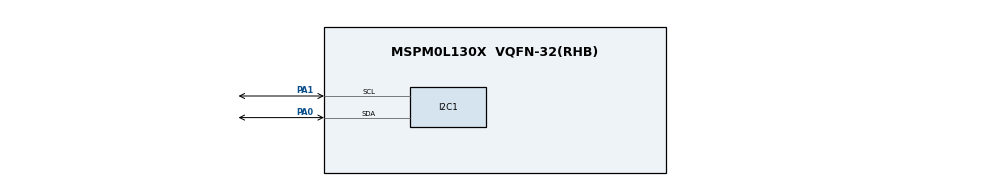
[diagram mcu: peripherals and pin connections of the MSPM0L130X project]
/**
 * @cliArgs --device "MSPM0L130X" --part "Default" --package "VQFN-32(RHB)" --product "mspm0_sdk@2.03.00.08"
 * @versions {"tool":"1.22.0+3893"}
 */

/**
 * Import the modules used in this configuration.
 */
const GPIO   = scripting.addModule("/ti/driverlib/GPIO", {}, false);
const GPIO1  = GPIO.addInstance();
const GPIO2  = GPIO.addInstance();
const GPIO3  = GPIO.addInstance();
const I2C    = scripting.addModule("/ti/driverlib/I2C", {}, false);
const I2C1   = I2C.addInstance();
const SYSCTL = scripting.addModule("/ti/driverlib/SYSCTL");
const TIMER  = scripting.addModule("/ti/driverlib/TIMER", {}, false);
const TIMER1 = TIMER.addInstance();

/**
 * Write custom configuration values to the imported modules.
 */
GPIO1.$name                         = "GPIO_LED";
GPIO1.port                          = "PORTA";
GPIO1.associatedPins[0].assignedPin = "7";
GPIO1.associatedPins[0].$name       = "STATUS";

const Board = scripting.addModule("/ti/driverlib/Board", {}, false);

GPIO2.$name                         = "GPIO_DAC";
GPIO2.port                          = "PORTA";
GPIO2.associatedPins.create(8);
GPIO2.associatedPins[0].$name       = "B7";
GPIO2.associatedPins[0].assignedPin = "11";
GPIO2.associatedPins[1].$name       = "B6";
GPIO2.associatedPins[1].assignedPin = "12";
GPIO2.associatedPins[2].$name       = "B5";
GPIO2.associatedPins[2].assignedPin = "13";
GPIO2.associatedPins[3].$name       = "B4";
GPIO2.associatedPins[3].assignedPin = "14";
GPIO2.associatedPins[4].$name       = "B3";
GPIO2.associatedPins[4].assignedPin = "15";
GPIO2.associatedPins[5].$name       = "B2";
GPIO2.associatedPins[5].assignedPin = "16";
GPIO2.associatedPins[6].$name       = "B1";
GPIO2.associatedPins[6].assignedPin = "17";
GPIO2.associatedPins[7].$name       = "B0";
GPIO2.associatedPins[7].assignedPin = "18";

GPIO3.$name                         = "GPIO_INPUT";
GPIO3.port                          = "PORTA";
GPIO3.associatedPins.create(5);
GPIO3.associatedPins[0].$name       = "SWITCH_UP";
GPIO3.associatedPins[0].assignedPin = "22";
GPIO3.associatedPins[0].direction   = "INPUT";
GPIO3.associatedPins[0].interruptEn = true;
GPIO3.associatedPins[0].polarity    = "FALL";
GPIO3.associatedPins[1].$name       = "SWITCH_DOWN";
GPIO3.associatedPins[1].direction   = "INPUT";
GPIO3.associatedPins[1].interruptEn = true;
GPIO3.associatedPins[1].polarity    = "FALL";
GPIO3.associatedPins[1].assignedPin = "21";
GPIO3.associatedPins[2].$name       = "ENCODER_A";
GPIO3.associatedPins[2].direction   = "INPUT";
GPIO3.associatedPins[2].assignedPin = "25";
GPIO3.associatedPins[2].interruptEn = true;
GPIO3.associatedPins[2].polarity    = "RISE_FALL";
GPIO3.associatedPins[3].$name       = "ENCODER_B";
GPIO3.associatedPins[3].direction   = "INPUT";
GPIO3.associatedPins[3].assignedPin = "24";
GPIO3.associatedPins[3].polarity    = "RISE_FALL";
GPIO3.associatedPins[4].$name       = "ENCODER_SW";
GPIO3.associatedPins[4].direction   = "INPUT";
GPIO3.associatedPins[4].assignedPin = "23";
GPIO3.associatedPins[4].interruptEn = true;
GPIO3.associatedPins[4].polarity    = "FALL";

I2C1.$name                     = "I2C_0";
I2C1.basicEnableController     = true;
I2C1.enableDMAEvent1           = false;
I2C1.enableDMAEvent2           = false;
I2C1.advControllerTXFIFOTRIG   = "BYTES_1";
I2C1.advAnalogGlitchFilter     = "DISABLED";
I2C1.intController             = ["ARBITRATION_LOST","NACK","TX_DONE"];
I2C1.peripheral.$assign        = "I2C0";
I2C1.peripheral.sdaPin.$assign = "PA0";
I2C1.peripheral.sclPin.$assign = "PA1";
I2C1.sdaPinConfig.$name        = "ti_driverlib_gpio_GPIOPinGeneric0";
I2C1.sclPinConfig.$name        = "ti_driverlib_gpio_GPIOPinGeneric1";


TIMER1.$name              = "TIMER_DAC";
TIMER1.timerMode          = "PERIODIC";
TIMER1.interrupts         = ["ZERO"];
TIMER1.timerPeriod        = "1ms";
TIMER1.timerClkDiv        = 2;
TIMER1.timerClkPrescale   = 160;
TIMER1.peripheral.$assign = "TIMG0";

/**
 * Pinmux solution for unlocked pins/peripherals. This ensures that minor changes to the automatic solver in a future
 * version of the tool will not impact the pinmux you originally saw.  These lines can be completely deleted in order to
 * re-solve from scratch.
 */
GPIO1.associatedPins[0].pin.$suggestSolution = "PA7";
Board.peripheral.$suggestSolution            = "DEBUGSS";
Board.peripheral.swclkPin.$suggestSolution   = "PA20";
Board.peripheral.swdioPin.$suggestSolution   = "PA19";
GPIO2.associatedPins[0].pin.$suggestSolution = "PA11";
GPIO2.associatedPins[1].pin.$suggestSolution = "PA12";
GPIO2.associatedPins[2].pin.$suggestSolution = "PA13";
GPIO2.associatedPins[3].pin.$suggestSolution = "PA14";
GPIO2.associatedPins[4].pin.$suggestSolution = "PA15";
GPIO2.associatedPins[5].pin.$suggestSolution = "PA16";
GPIO2.associatedPins[6].pin.$suggestSolution = "PA17/OPA1.IN0-";
GPIO2.associatedPins[7].pin.$suggestSolution = "PA18";
GPIO3.associatedPins[0].pin.$suggestSolution = "PA22";
GPIO3.associatedPins[1].pin.$suggestSolution = "PA21";
GPIO3.associatedPins[2].pin.$suggestSolution = "PA25";
GPIO3.associatedPins[3].pin.$suggestSolution = "PA24/OPA0.IN0-";
GPIO3.associatedPins[4].pin.$suggestSolution = "PA23";
SYSCTL.peripheral.$suggestSolution           = "SYSCTL";
